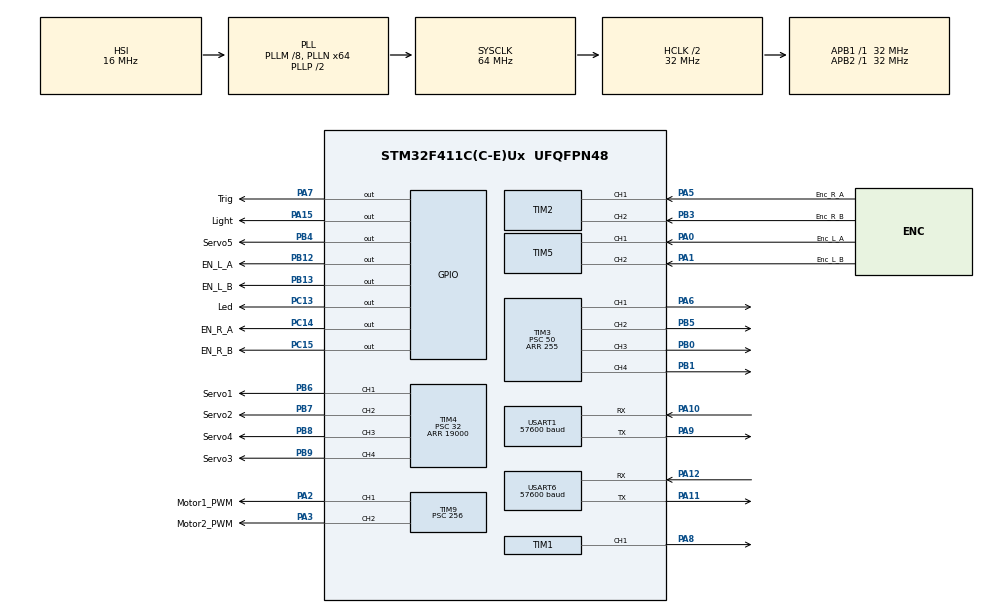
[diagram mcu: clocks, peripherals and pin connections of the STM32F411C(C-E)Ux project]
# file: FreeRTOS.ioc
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Dma.Request0=USART1_RX
Dma.Request1=USART1_TX
Dma.Request2=USART6_TX
Dma.Request3=USART6_RX
Dma.USART1_RX.0.Direction=DMA_PERIPH_TO_MEMORY
Dma.USART1_RX.0.FIFOMode=DMA_FIFOMODE_DISABLE
Dma.USART1_RX.0.Instance=DMA2_Stream2
Dma.USART1_RX.0.MemDataAlignment=DMA_MDATAALIGN_BYTE
Dma.USART1_RX.0.MemInc=DMA_MINC_ENABLE
Dma.USART1_RX.0.Mode=DMA_NORMAL
Dma.USART1_RX.0.PeriphDataAlignment=DMA_PDATAALIGN_BYTE
Dma.USART1_RX.0.PeriphInc=DMA_PINC_DISABLE
Dma.USART1_RX.0.Priority=DMA_PRIORITY_LOW
Dma.USART1_TX.1.Direction=DMA_MEMORY_TO_PERIPH
Dma.USART1_TX.1.FIFOMode=DMA_FIFOMODE_DISABLE
Dma.USART1_TX.1.Instance=DMA2_Stream7
Dma.USART1_TX.1.MemDataAlignment=DMA_MDATAALIGN_BYTE
Dma.USART1_TX.1.MemInc=DMA_MINC_ENABLE
Dma.USART1_TX.1.Mode=DMA_NORMAL
Dma.USART1_TX.1.PeriphDataAlignment=DMA_PDATAALIGN_BYTE
Dma.USART1_TX.1.PeriphInc=DMA_PINC_DISABLE
Dma.USART1_TX.1.Priority=DMA_PRIORITY_LOW
Dma.USART6_RX.3.Direction=DMA_PERIPH_TO_MEMORY
Dma.USART6_RX.3.FIFOMode=DMA_FIFOMODE_DISABLE
Dma.USART6_RX.3.Instance=DMA2_Stream1
Dma.USART6_RX.3.MemDataAlignment=DMA_MDATAALIGN_BYTE
Dma.USART6_RX.3.MemInc=DMA_MINC_ENABLE
Dma.USART6_RX.3.Mode=DMA_NORMAL
Dma.USART6_RX.3.PeriphDataAlignment=DMA_PDATAALIGN_BYTE
Dma.USART6_RX.3.PeriphInc=DMA_PINC_DISABLE
Dma.USART6_RX.3.Priority=DMA_PRIORITY_LOW
Dma.USART6_TX.2.Direction=DMA_MEMORY_TO_PERIPH
Dma.USART6_TX.2.FIFOMode=DMA_FIFOMODE_DISABLE
Dma.USART6_TX.2.Instance=DMA2_Stream6
Dma.USART6_TX.2.MemDataAlignment=DMA_MDATAALIGN_BYTE
Dma.USART6_TX.2.MemInc=DMA_MINC_ENABLE
Dma.USART6_TX.2.Mode=DMA_NORMAL
Dma.USART6_TX.2.PeriphDataAlignment=DMA_PDATAALIGN_BYTE
Dma.USART6_TX.2.PeriphInc=DMA_PINC_DISABLE
Dma.USART6_TX.2.Priority=DMA_PRIORITY_LOW
Mcu.Family=STM32F4
Mcu.Name=STM32F411C(C-E)Ux
Mcu.Package=UFQFPN48
NVIC.DMA2_Stream1_IRQn=true\:0\:0\:false\:false\:true\:false\:true\:true
NVIC.DMA2_Stream2_IRQn=true\:0\:0\:false\:false\:true\:false\:true\:true
NVIC.DMA2_Stream6_IRQn=true\:0\:0\:false\:false\:true\:false\:true\:true
NVIC.DMA2_Stream7_IRQn=true\:0\:0\:false\:false\:true\:false\:true\:true
NVIC.PriorityGroup=NVIC_PRIORITYGROUP_4
NVIC.TIM1_TRG_COM_TIM11_IRQn=true\:0\:0\:false\:false\:true\:true\:true\:true
NVIC.TIM1_UP_TIM10_IRQn=true\:0\:0\:false\:false\:true\:true\:true\:true
NVIC.TIM2_IRQn=true\:0\:0\:false\:true\:true\:1\:true\:true\:true
NVIC.TIM5_IRQn=true\:0\:0\:false\:false\:true\:true\:true\:true
NVIC.USART1_IRQn=true\:0\:0\:false\:false\:true\:true\:true\:true
NVIC.USART6_IRQn=true\:0\:0\:false\:false\:true\:true\:true\:true
PA0-WKUP.GPIO_Label=Enc_L_A
PA0-WKUP.Signal=S_TIM5_CH1
PA1.GPIO_Label=Enc_L_B
PA1.Signal=S_TIM5_CH2
PA10.Mode=Asynchronous
PA10.Signal=USART1_RX
PA11.Mode=Asynchronous
PA11.Signal=USART6_TX
PA12.Mode=Asynchronous
PA12.Signal=USART6_RX
PA13.Mode=Serial_Wire
PA13.Signal=SYS_JTMS-SWDIO
PA14.Mode=Serial_Wire
PA14.Signal=SYS_JTCK-SWCLK
PA15.GPIO_Label=Light
PA15.Signal=GPIO_Output
PA2.GPIO_Label=Motor1_PWM
PA2.Signal=S_TIM9_CH1
PA3.GPIO_Label=Motor2_PWM
PA3.Signal=S_TIM9_CH2
PA5.GPIO_Label=Enc_R_A
PA5.GPIO_PuPd=GPIO_PULLUP
PA5.GPIO_Speed=GPIO_SPEED_FREQ_VERY_HIGH
PA5.Signal=S_TIM2_CH1_ETR
PA6.Signal=S_TIM3_CH1
PA7.GPIO_Label=Trig
PA7.Signal=GPIO_Output
PA8.Signal=S_TIM1_CH1
PA9.Mode=Asynchronous
PA9.Signal=USART1_TX
PB0.Signal=S_TIM3_CH3
PB1.Signal=S_TIM3_CH4
PB12.GPIO_Label=EN_L_A
PB12.Signal=GPIO_Output
PB13.GPIO_Label=EN_L_B
PB13.Signal=GPIO_Output
PB3.GPIO_Label=Enc_R_B
PB3.GPIO_PuPd=GPIO_PULLUP
PB3.GPIO_Speed=GPIO_SPEED_FREQ_VERY_HIGH
PB3.Signal=S_TIM2_CH2
PB4.GPIO_Label=Servo5
PB4.Signal=GPIO_Output
PB5.Signal=S_TIM3_CH2
PB6.GPIO_Label=Servo1
PB6.GPIO_ModeDefaultPP=GPIO_MODE_AF_OD
PB6.GPIO_PuPd=GPIO_NOPULL
PB6.GPIO_Speed=GPIO_SPEED_FREQ_VERY_HIGH
PB6.Signal=S_TIM4_CH1
PB7.GPIO_Label=Servo2
PB7.GPIO_ModeDefaultPP=GPIO_MODE_AF_OD
PB7.GPIO_PuPd=GPIO_NOPULL
PB7.GPIO_Speed=GPIO_SPEED_FREQ_VERY_HIGH
PB7.Signal=S_TIM4_CH2
PB8.GPIO_Label=Servo4
PB8.GPIO_ModeDefaultPP=GPIO_MODE_AF_OD
PB8.GPIO_PuPd=GPIO_NOPULL
PB8.GPIO_Speed=GPIO_SPEED_FREQ_VERY_HIGH
PB8.Signal=S_TIM4_CH3
PB9.GPIO_Label=Servo3
PB9.GPIO_ModeDefaultPP=GPIO_MODE_AF_OD
PB9.GPIO_PuPd=GPIO_NOPULL
PB9.GPIO_Speed=GPIO_SPEED_FREQ_VERY_HIGH
PB9.Signal=S_TIM4_CH4
PC13-ANTI_TAMP.GPIO_Label=Led
PC13-ANTI_TAMP.Signal=GPIO_Output
PC14-OSC32_IN.GPIO_Label=EN_R_A
PC14-OSC32_IN.Signal=GPIO_Output
PC15-OSC32_OUT.GPIO_Label=EN_R_B
PC15-OSC32_OUT.Signal=GPIO_Output
ProjectManager.HeapSize=0x200
ProjectManager.StackSize=0x400
ProjectManager.TargetToolchain=MDK-ARM V5.32
RCC.48MHZClocksFreq_Value=32000000
RCC.AHBCLKDivider=RCC_SYSCLK_DIV2
RCC.AHBFreq_Value=32000000
RCC.APB1Freq_Value=32000000
RCC.APB1TimFreq_Value=32000000
RCC.APB2Freq_Value=32000000
RCC.APB2TimFreq_Value=32000000
RCC.CortexFreq_Value=32000000
RCC.HCLKFreq_Value=32000000
RCC.HSE_VALUE=25000000
RCC.HSI_VALUE=16000000
RCC.LSE_VALUE=32768
RCC.PLLM=8
RCC.PLLN=64
RCC.SYSCLKFreq_VALUE=64000000
RCC.SYSCLKSource=RCC_SYSCLKSOURCE_PLLCLK
RCC.VCOOutputFreq_Value=128000000
SH.S_TIM1_CH1.0=TIM1_CH1,PWM Generation1 CH1
SH.S_TIM2_CH1_ETR.0=TIM2_CH1,Encoder_Interface
SH.S_TIM2_CH2.0=TIM2_CH2,Encoder_Interface
SH.S_TIM3_CH1.0=TIM3_CH1,PWM Generation1 CH1
SH.S_TIM3_CH2.0=TIM3_CH2,PWM Generation2 CH2
SH.S_TIM3_CH3.0=TIM3_CH3,PWM Generation3 CH3
SH.S_TIM3_CH4.0=TIM3_CH4,PWM Generation4 CH4
SH.S_TIM4_CH1.0=TIM4_CH1,PWM Generation1 CH1
SH.S_TIM4_CH2.0=TIM4_CH2,PWM Generation2 CH2
SH.S_TIM4_CH3.0=TIM4_CH3,PWM Generation3 CH3
SH.S_TIM4_CH4.0=TIM4_CH4,PWM Generation4 CH4
SH.S_TIM5_CH1.0=TIM5_CH1,Encoder_Interface
SH.S_TIM5_CH2.0=TIM5_CH2,Encoder_Interface
SH.S_TIM9_CH1.0=TIM9_CH1,PWM Generation1 CH1
SH.S_TIM9_CH2.0=TIM9_CH2,PWM Generation2 CH2
TIM1.Channel-PWM\ Generation1\ CH1=TIM_CHANNEL_1
TIM1.Period=639
TIM1.Prescaler=2
TIM10.Channel=TIM_CHANNEL_1
TIM10.Period=20000
TIM10.Prescaler=320
TIM11.Channel=TIM_CHANNEL_1
TIM11.Period=19000
TIM11.Prescaler=32
TIM2.EncoderMode=TIM_ENCODERMODE_TI2
TIM2.IC1Filter=0
TIM2.IC2Filter=0
TIM3.Channel-PWM\ Generation1\ CH1=TIM_CHANNEL_1
TIM3.Channel-PWM\ Generation2\ CH2=TIM_CHANNEL_2
TIM3.Channel-PWM\ Generation3\ CH3=TIM_CHANNEL_3
TIM3.Channel-PWM\ Generation4\ CH4=TIM_CHANNEL_4
TIM3.Period=255
TIM3.Prescaler=50
TIM4.Channel-PWM\ Generation1\ CH1=TIM_CHANNEL_1
TIM4.Channel-PWM\ Generation2\ CH2=TIM_CHANNEL_2
TIM4.Channel-PWM\ Generation3\ CH3=TIM_CHANNEL_3
TIM4.Channel-PWM\ Generation4\ CH4=TIM_CHANNEL_4
TIM4.Period=19000
TIM4.Prescaler=32
TIM5.EncoderMode=TIM_ENCODERMODE_TI2
TIM9.Channel-PWM\ Generation1\ CH1=TIM_CHANNEL_1
TIM9.Channel-PWM\ Generation2\ CH2=TIM_CHANNEL_2
TIM9.Period=1000
TIM9.Prescaler=256
USART1.BaudRate=57600
USART1.VirtualMode=VM_ASYNC
USART6.BaudRate=57600
USART6.VirtualMode=VM_ASYNC
VP_TIM10_VS_ClockSourceINT.Mode=Enable_Timer
VP_TIM10_VS_no_output1.Mode=Output Compare1 No Output
VP_TIM11_VS_ClockSourceINT.Mode=Enable_Timer
VP_TIM11_VS_no_output1.Mode=Output Compare1 No Output
board=custom

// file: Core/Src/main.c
/* USER CODE BEGIN Header */
/**
  ******************************************************************************
  * @file           : main.c
  * @brief          : Main program body
  ******************************************************************************
  * @attention
  *
  * Copyright (c) 2024 STMicroelectronics.
  * All rights reserved.
  *
  * This software is licensed under terms that can be found in the LICENSE file
  * in the root directory of this software component.
  * If no LICENSE file comes with this software, it is provided AS-IS.
  *
  ******************************************************************************
  */
/* USER CODE END Header */
#include "main.h"

/* USER CODE BEGIN Includes */
#include "FreeRTOS.h"
/* USER CODE END Includes */

TIM_HandleTypeDef htim1;
TIM_HandleTypeDef htim2;
TIM_HandleTypeDef htim3;
TIM_HandleTypeDef htim4;
TIM_HandleTypeDef htim5;
TIM_HandleTypeDef htim9;
TIM_HandleTypeDef htim10;
TIM_HandleTypeDef htim11;

UART_HandleTypeDef huart1;
UART_HandleTypeDef huart6;
DMA_HandleTypeDef hdma_usart1_rx;
DMA_HandleTypeDef hdma_usart1_tx;
DMA_HandleTypeDef hdma_usart6_tx;
DMA_HandleTypeDef hdma_usart6_rx;

void SystemClock_Config(void);
static void MX_GPIO_Init(void);
static void MX_DMA_Init(void);
static void MX_TIM2_Init(void);
static void MX_TIM4_Init(void);
static void MX_TIM5_Init(void);
static void MX_TIM9_Init(void);
static void MX_USART1_UART_Init(void);
static void MX_TIM3_Init(void);
static void MX_TIM10_Init(void);
static void MX_TIM11_Init(void);
static void MX_USART6_UART_Init(void);
static void MX_TIM1_Init(void);
static void MX_NVIC_Init(void);

int main(void)
{

  /* MCU Configuration--------------------------------------------------------*/

  /* Reset of all peripherals, Initializes the Flash interface and the Systick. */
  HAL_Init();

  /* Configure the system clock */
  SystemClock_Config();

  /* Initialize all configured peripherals */
  MX_GPIO_Init();
  MX_DMA_Init();
  MX_TIM2_Init();
  MX_TIM4_Init();
  MX_TIM5_Init();
  MX_TIM9_Init();
  MX_USART1_UART_Init();
  MX_TIM3_Init();
  MX_TIM10_Init();
  MX_TIM11_Init();
  MX_USART6_UART_Init();
  MX_TIM1_Init();

  /* Initialize interrupts */
  MX_NVIC_Init();

  /* Infinite loop */
  while (1)
  {

  }
}

void SystemClock_Config(void)
{
  RCC_OscInitTypeDef RCC_OscInitStruct = {0};
  RCC_ClkInitTypeDef RCC_ClkInitStruct = {0};

  /** Configure the main internal regulator output voltage
  */
  __HAL_RCC_PWR_CLK_ENABLE();
  __HAL_PWR_VOLTAGESCALING_CONFIG(PWR_REGULATOR_VOLTAGE_SCALE1);

  /** Initializes the RCC Oscillators according to the specified parameters
  * in the RCC_OscInitTypeDef structure.
  */
  RCC_OscInitStruct.OscillatorType = RCC_OSCILLATORTYPE_HSI;
  RCC_OscInitStruct.HSIState = RCC_HSI_ON;
  RCC_OscInitStruct.HSICalibrationValue = RCC_HSICALIBRATION_DEFAULT;
  RCC_OscInitStruct.PLL.PLLState = RCC_PLL_ON;
  RCC_OscInitStruct.PLL.PLLSource = RCC_PLLSOURCE_HSI;
  RCC_OscInitStruct.PLL.PLLM = 8;
  RCC_OscInitStruct.PLL.PLLN = 64;
  RCC_OscInitStruct.PLL.PLLP = RCC_PLLP_DIV2;
  RCC_OscInitStruct.PLL.PLLQ = 4;
  if (HAL_RCC_OscConfig(&RCC_OscInitStruct) != HAL_OK)
  {
    Error_Handler();
  }

  /** Initializes the CPU, AHB and APB buses clocks
  */
  RCC_ClkInitStruct.ClockType = RCC_CLOCKTYPE_HCLK|RCC_CLOCKTYPE_SYSCLK
                              |RCC_CLOCKTYPE_PCLK1|RCC_CLOCKTYPE_PCLK2;
  RCC_ClkInitStruct.SYSCLKSource = RCC_SYSCLKSOURCE_PLLCLK;
  RCC_ClkInitStruct.AHBCLKDivider = RCC_SYSCLK_DIV2;
  RCC_ClkInitStruct.APB1CLKDivider = RCC_HCLK_DIV1;
  RCC_ClkInitStruct.APB2CLKDivider = RCC_HCLK_DIV1;

  if (HAL_RCC_ClockConfig(&RCC_ClkInitStruct, FLASH_LATENCY_1) != HAL_OK)
  {
    Error_Handler();
  }
}

/**
  * @brief NVIC Configuration.
  * @retval None
  */
static void MX_NVIC_Init(void)
{
  /* TIM2_IRQn interrupt configuration */
  HAL_NVIC_SetPriority(TIM2_IRQn, 0, 0);
  HAL_NVIC_EnableIRQ(TIM2_IRQn);
}

static void MX_TIM1_Init(void)
{

  TIM_MasterConfigTypeDef sMasterConfig = {0};
  TIM_OC_InitTypeDef sConfigOC = {0};
  TIM_BreakDeadTimeConfigTypeDef sBreakDeadTimeConfig = {0};

  htim1.Instance = TIM1;
  htim1.Init.Prescaler = 2;
  htim1.Init.CounterMode = TIM_COUNTERMODE_UP;
  htim1.Init.Period = 639;
  htim1.Init.ClockDivision = TIM_CLOCKDIVISION_DIV1;
  htim1.Init.RepetitionCounter = 0;
  htim1.Init.AutoReloadPreload = TIM_AUTORELOAD_PRELOAD_DISABLE;
  if (HAL_TIM_PWM_Init(&htim1) != HAL_OK)
  {
    Error_Handler();
  }
  sMasterConfig.MasterOutputTrigger = TIM_TRGO_RESET;
  sMasterConfig.MasterSlaveMode = TIM_MASTERSLAVEMODE_DISABLE;
  if (HAL_TIMEx_MasterConfigSynchronization(&htim1, &sMasterConfig) != HAL_OK)
  {
    Error_Handler();
  }
  sConfigOC.OCMode = TIM_OCMODE_PWM1;
  sConfigOC.Pulse = 0;
  sConfigOC.OCPolarity = TIM_OCPOLARITY_HIGH;
  sConfigOC.OCNPolarity = TIM_OCNPOLARITY_HIGH;
  sConfigOC.OCFastMode = TIM_OCFAST_DISABLE;
  sConfigOC.OCIdleState = TIM_OCIDLESTATE_RESET;
  sConfigOC.OCNIdleState = TIM_OCNIDLESTATE_RESET;
  if (HAL_TIM_PWM_ConfigChannel(&htim1, &sConfigOC, TIM_CHANNEL_1) != HAL_OK)
  {
    Error_Handler();
  }
  sBreakDeadTimeConfig.OffStateRunMode = TIM_OSSR_DISABLE;
  sBreakDeadTimeConfig.OffStateIDLEMode = TIM_OSSI_DISABLE;
  sBreakDeadTimeConfig.LockLevel = TIM_LOCKLEVEL_OFF;
  sBreakDeadTimeConfig.DeadTime = 0;
  sBreakDeadTimeConfig.BreakState = TIM_BREAK_DISABLE;
  sBreakDeadTimeConfig.BreakPolarity = TIM_BREAKPOLARITY_HIGH;
  sBreakDeadTimeConfig.AutomaticOutput = TIM_AUTOMATICOUTPUT_DISABLE;
  if (HAL_TIMEx_ConfigBreakDeadTime(&htim1, &sBreakDeadTimeConfig) != HAL_OK)
  {
    Error_Handler();
  }
  HAL_TIM_MspPostInit(&htim1);

}

static void MX_TIM2_Init(void)
{

  TIM_Encoder_InitTypeDef sConfig = {0};
  TIM_MasterConfigTypeDef sMasterConfig = {0};

  htim2.Instance = TIM2;
  htim2.Init.Prescaler = 0;
  htim2.Init.CounterMode = TIM_COUNTERMODE_UP;
  htim2.Init.Period = 4294967295;
  htim2.Init.ClockDivision = TIM_CLOCKDIVISION_DIV1;
  htim2.Init.AutoReloadPreload = TIM_AUTORELOAD_PRELOAD_DISABLE;
  sConfig.EncoderMode = TIM_ENCODERMODE_TI2;
  sConfig.IC1Polarity = TIM_ICPOLARITY_RISING;
  sConfig.IC1Selection = TIM_ICSELECTION_DIRECTTI;
  sConfig.IC1Prescaler = TIM_ICPSC_DIV1;
  sConfig.IC1Filter = 0;
  sConfig.IC2Polarity = TIM_ICPOLARITY_RISING;
  sConfig.IC2Selection = TIM_ICSELECTION_DIRECTTI;
  sConfig.IC2Prescaler = TIM_ICPSC_DIV1;
  sConfig.IC2Filter = 0;
  if (HAL_TIM_Encoder_Init(&htim2, &sConfig) != HAL_OK)
  {
    Error_Handler();
  }
  sMasterConfig.MasterOutputTrigger = TIM_TRGO_RESET;
  sMasterConfig.MasterSlaveMode = TIM_MASTERSLAVEMODE_DISABLE;
  if (HAL_TIMEx_MasterConfigSynchronization(&htim2, &sMasterConfig) != HAL_OK)
  {
    Error_Handler();
  }

}

static void MX_TIM3_Init(void)
{

  TIM_MasterConfigTypeDef sMasterConfig = {0};
  TIM_OC_InitTypeDef sConfigOC = {0};

  htim3.Instance = TIM3;
  htim3.Init.Prescaler = 50;
  htim3.Init.CounterMode = TIM_COUNTERMODE_UP;
  htim3.Init.Period = 255;
  htim3.Init.ClockDivision = TIM_CLOCKDIVISION_DIV1;
  htim3.Init.AutoReloadPreload = TIM_AUTORELOAD_PRELOAD_DISABLE;
  if (HAL_TIM_PWM_Init(&htim3) != HAL_OK)
  {
    Error_Handler();
  }
  sMasterConfig.MasterOutputTrigger = TIM_TRGO_RESET;
  sMasterConfig.MasterSlaveMode = TIM_MASTERSLAVEMODE_DISABLE;
  if (HAL_TIMEx_MasterConfigSynchronization(&htim3, &sMasterConfig) != HAL_OK)
  {
    Error_Handler();
  }
  sConfigOC.OCMode = TIM_OCMODE_PWM1;
  sConfigOC.Pulse = 0;
  sConfigOC.OCPolarity = TIM_OCPOLARITY_HIGH;
  sConfigOC.OCFastMode = TIM_OCFAST_DISABLE;
  if (HAL_TIM_PWM_ConfigChannel(&htim3, &sConfigOC, TIM_CHANNEL_1) != HAL_OK)
  {
    Error_Handler();
  }
  if (HAL_TIM_PWM_ConfigChannel(&htim3, &sConfigOC, TIM_CHANNEL_2) != HAL_OK)
  {
    Error_Handler();
  }
  if (HAL_TIM_PWM_ConfigChannel(&htim3, &sConfigOC, TIM_CHANNEL_3) != HAL_OK)
  {
    Error_Handler();
  }
  if (HAL_TIM_PWM_ConfigChannel(&htim3, &sConfigOC, TIM_CHANNEL_4) != HAL_OK)
  {
    Error_Handler();
  }
  HAL_TIM_MspPostInit(&htim3);

}

static void MX_TIM4_Init(void)
{

  TIM_MasterConfigTypeDef sMasterConfig = {0};
  TIM_OC_InitTypeDef sConfigOC = {0};

  htim4.Instance = TIM4;
  htim4.Init.Prescaler = 32;
  htim4.Init.CounterMode = TIM_COUNTERMODE_UP;
  htim4.Init.Period = 19000;
  htim4.Init.ClockDivision = TIM_CLOCKDIVISION_DIV1;
  htim4.Init.AutoReloadPreload = TIM_AUTORELOAD_PRELOAD_DISABLE;
  if (HAL_TIM_PWM_Init(&htim4) != HAL_OK)
  {
    Error_Handler();
  }
  sMasterConfig.MasterOutputTrigger = TIM_TRGO_RESET;
  sMasterConfig.MasterSlaveMode = TIM_MASTERSLAVEMODE_DISABLE;
  if (HAL_TIMEx_MasterConfigSynchronization(&htim4, &sMasterConfig) != HAL_OK)
  {
    Error_Handler();
  }
  sConfigOC.OCMode = TIM_OCMODE_PWM1;
  sConfigOC.Pulse = 0;
  sConfigOC.OCPolarity = TIM_OCPOLARITY_HIGH;
  sConfigOC.OCFastMode = TIM_OCFAST_DISABLE;
  if (HAL_TIM_PWM_ConfigChannel(&htim4, &sConfigOC, TIM_CHANNEL_1) != HAL_OK)
  {
    Error_Handler();
  }
  if (HAL_TIM_PWM_ConfigChannel(&htim4, &sConfigOC, TIM_CHANNEL_2) != HAL_OK)
  {
    Error_Handler();
  }
  if (HAL_TIM_PWM_ConfigChannel(&htim4, &sConfigOC, TIM_CHANNEL_3) != HAL_OK)
  {
    Error_Handler();
  }
  if (HAL_TIM_PWM_ConfigChannel(&htim4, &sConfigOC, TIM_CHANNEL_4) != HAL_OK)
  {
    Error_Handler();
  }
  HAL_TIM_MspPostInit(&htim4);

}

static void MX_TIM5_Init(void)
{

  TIM_Encoder_InitTypeDef sConfig = {0};
  TIM_MasterConfigTypeDef sMasterConfig = {0};

  htim5.Instance = TIM5;
  htim5.Init.Prescaler = 0;
  htim5.Init.CounterMode = TIM_COUNTERMODE_UP;
  htim5.Init.Period = 4294967295;
  htim5.Init.ClockDivision = TIM_CLOCKDIVISION_DIV1;
  htim5.Init.AutoReloadPreload = TIM_AUTORELOAD_PRELOAD_DISABLE;
  sConfig.EncoderMode = TIM_ENCODERMODE_TI2;
  sConfig.IC1Polarity = TIM_ICPOLARITY_RISING;
  sConfig.IC1Selection = TIM_ICSELECTION_DIRECTTI;
  sConfig.IC1Prescaler = TIM_ICPSC_DIV1;
  sConfig.IC1Filter = 0;
  sConfig.IC2Polarity = TIM_ICPOLARITY_RISING;
  sConfig.IC2Selection = TIM_ICSELECTION_DIRECTTI;
  sConfig.IC2Prescaler = TIM_ICPSC_DIV1;
  sConfig.IC2Filter = 0;
  if (HAL_TIM_Encoder_Init(&htim5, &sConfig) != HAL_OK)
  {
    Error_Handler();
  }
  sMasterConfig.MasterOutputTrigger = TIM_TRGO_RESET;
  sMasterConfig.MasterSlaveMode = TIM_MASTERSLAVEMODE_DISABLE;
  if (HAL_TIMEx_MasterConfigSynchronization(&htim5, &sMasterConfig) != HAL_OK)
  {
    Error_Handler();
  }

}

static void MX_TIM9_Init(void)
{

  TIM_OC_InitTypeDef sConfigOC = {0};

  htim9.Instance = TIM9;
  htim9.Init.Prescaler = 256;
  htim9.Init.CounterMode = TIM_COUNTERMODE_UP;
  htim9.Init.Period = 1000;
  htim9.Init.ClockDivision = TIM_CLOCKDIVISION_DIV1;
  htim9.Init.AutoReloadPreload = TIM_AUTORELOAD_PRELOAD_DISABLE;
  if (HAL_TIM_PWM_Init(&htim9) != HAL_OK)
  {
    Error_Handler();
  }
  sConfigOC.OCMode = TIM_OCMODE_PWM1;
  sConfigOC.Pulse = 0;
  sConfigOC.OCPolarity = TIM_OCPOLARITY_HIGH;
  sConfigOC.OCFastMode = TIM_OCFAST_DISABLE;
  if (HAL_TIM_PWM_ConfigChannel(&htim9, &sConfigOC, TIM_CHANNEL_1) != HAL_OK)
  {
    Error_Handler();
  }
  if (HAL_TIM_PWM_ConfigChannel(&htim9, &sConfigOC, TIM_CHANNEL_2) != HAL_OK)
  {
    Error_Handler();
  }
  HAL_TIM_MspPostInit(&htim9);

}

static void MX_TIM10_Init(void)
{

  TIM_OC_InitTypeDef sConfigOC = {0};

  htim10.Instance = TIM10;
  htim10.Init.Prescaler = 320;
  htim10.Init.CounterMode = TIM_COUNTERMODE_UP;
  htim10.Init.Period = 20000;
  htim10.Init.ClockDivision = TIM_CLOCKDIVISION_DIV1;
  htim10.Init.AutoReloadPreload = TIM_AUTORELOAD_PRELOAD_DISABLE;
  if (HAL_TIM_Base_Init(&htim10) != HAL_OK)
  {
    Error_Handler();
  }
  if (HAL_TIM_OC_Init(&htim10) != HAL_OK)
  {
    Error_Handler();
  }
  sConfigOC.OCMode = TIM_OCMODE_TIMING;
  sConfigOC.Pulse = 0;
  sConfigOC.OCPolarity = TIM_OCPOLARITY_HIGH;
  sConfigOC.OCFastMode = TIM_OCFAST_DISABLE;
  if (HAL_TIM_OC_ConfigChannel(&htim10, &sConfigOC, TIM_CHANNEL_1) != HAL_OK)
  {
    Error_Handler();
  }

}

static void MX_TIM11_Init(void)
{

  TIM_OC_InitTypeDef sConfigOC = {0};

  htim11.Instance = TIM11;
  htim11.Init.Prescaler = 32;
  htim11.Init.CounterMode = TIM_COUNTERMODE_UP;
  htim11.Init.Period = 19000;
  htim11.Init.ClockDivision = TIM_CLOCKDIVISION_DIV1;
  htim11.Init.AutoReloadPreload = TIM_AUTORELOAD_PRELOAD_DISABLE;
  if (HAL_TIM_Base_Init(&htim11) != HAL_OK)
  {
    Error_Handler();
  }
  if (HAL_TIM_OC_Init(&htim11) != HAL_OK)
  {
    Error_Handler();
  }
  sConfigOC.OCMode = TIM_OCMODE_TIMING;
  sConfigOC.Pulse = 0;
  sConfigOC.OCPolarity = TIM_OCPOLARITY_HIGH;
  sConfigOC.OCFastMode = TIM_OCFAST_DISABLE;
  if (HAL_TIM_OC_ConfigChannel(&htim11, &sConfigOC, TIM_CHANNEL_1) != HAL_OK)
  {
    Error_Handler();
  }

}

static void MX_USART1_UART_Init(void)
{

  huart1.Instance = USART1;
  huart1.Init.BaudRate = 57600;
  huart1.Init.WordLength = UART_WORDLENGTH_8B;
  huart1.Init.StopBits = UART_STOPBITS_1;
  huart1.Init.Parity = UART_PARITY_NONE;
  huart1.Init.Mode = UART_MODE_TX_RX;
  huart1.Init.HwFlowCtl = UART_HWCONTROL_NONE;
  huart1.Init.OverSampling = UART_OVERSAMPLING_16;
  if (HAL_UART_Init(&huart1) != HAL_OK)
  {
    Error_Handler();
  }

}

static void MX_USART6_UART_Init(void)
{

  huart6.Instance = USART6;
  huart6.Init.BaudRate = 57600;
  huart6.Init.WordLength = UART_WORDLENGTH_8B;
  huart6.Init.StopBits = UART_STOPBITS_1;
  huart6.Init.Parity = UART_PARITY_NONE;
  huart6.Init.Mode = UART_MODE_TX_RX;
  huart6.Init.HwFlowCtl = UART_HWCONTROL_NONE;
  huart6.Init.OverSampling = UART_OVERSAMPLING_16;
  if (HAL_UART_Init(&huart6) != HAL_OK)
  {
    Error_Handler();
  }

}

static void MX_DMA_Init(void)
{

  /* DMA controller clock enable */
  __HAL_RCC_DMA2_CLK_ENABLE();

  /* DMA interrupt init */
  /* DMA2_Stream1_IRQn interrupt configuration */
  HAL_NVIC_SetPriority(DMA2_Stream1_IRQn, 0, 0);
  HAL_NVIC_EnableIRQ(DMA2_Stream1_IRQn);
  /* DMA2_Stream2_IRQn interrupt configuration */
  HAL_NVIC_SetPriority(DMA2_Stream2_IRQn, 0, 0);
  HAL_NVIC_EnableIRQ(DMA2_Stream2_IRQn);
  /* DMA2_Stream6_IRQn interrupt configuration */
  HAL_NVIC_SetPriority(DMA2_Stream6_IRQn, 0, 0);
  HAL_NVIC_EnableIRQ(DMA2_Stream6_IRQn);
  /* DMA2_Stream7_IRQn interrupt configuration */
  HAL_NVIC_SetPriority(DMA2_Stream7_IRQn, 0, 0);
  HAL_NVIC_EnableIRQ(DMA2_Stream7_IRQn);

}

static void MX_GPIO_Init(void)
{
  GPIO_InitTypeDef GPIO_InitStruct = {0};

  /* GPIO Ports Clock Enable */
  __HAL_RCC_GPIOC_CLK_ENABLE();
  __HAL_RCC_GPIOA_CLK_ENABLE();
  __HAL_RCC_GPIOB_CLK_ENABLE();

  /*Configure GPIO pin Output Level */
  HAL_GPIO_WritePin(GPIOC, Led_Pin|EN_R_A_Pin|EN_R_B_Pin, GPIO_PIN_RESET);

  /*Configure GPIO pin Output Level */
  HAL_GPIO_WritePin(GPIOA, Trig_Pin|Light_Pin, GPIO_PIN_RESET);

  /*Configure GPIO pin Output Level */
  HAL_GPIO_WritePin(GPIOB, EN_L_A_Pin|EN_L_B_Pin|Servo5_Pin, GPIO_PIN_RESET);

  /*Configure GPIO pins : Led_Pin EN_R_A_Pin EN_R_B_Pin */
  GPIO_InitStruct.Pin = Led_Pin|EN_R_A_Pin|EN_R_B_Pin;
  GPIO_InitStruct.Mode = GPIO_MODE_OUTPUT_PP;
  GPIO_InitStruct.Pull = GPIO_NOPULL;
  GPIO_InitStruct.Speed = GPIO_SPEED_FREQ_LOW;
  HAL_GPIO_Init(GPIOC, &GPIO_InitStruct);

  /*Configure GPIO pins : Trig_Pin Light_Pin */
  GPIO_InitStruct.Pin = Trig_Pin|Light_Pin;
  GPIO_InitStruct.Mode = GPIO_MODE_OUTPUT_PP;
  GPIO_InitStruct.Pull = GPIO_NOPULL;
  GPIO_InitStruct.Speed = GPIO_SPEED_FREQ_LOW;
  HAL_GPIO_Init(GPIOA, &GPIO_InitStruct);

  /*Configure GPIO pins : EN_L_A_Pin EN_L_B_Pin Servo5_Pin */
  GPIO_InitStruct.Pin = EN_L_A_Pin|EN_L_B_Pin|Servo5_Pin;
  GPIO_InitStruct.Mode = GPIO_MODE_OUTPUT_PP;
  GPIO_InitStruct.Pull = GPIO_NOPULL;
  GPIO_InitStruct.Speed = GPIO_SPEED_FREQ_LOW;
  HAL_GPIO_Init(GPIOB, &GPIO_InitStruct);

}

void Error_Handler(void)
{
  __disable_irq();
  while (1)
  {
  }
}
